# f28002x_wd_regs register map
Vendor: Texas Instruments
Peripheral module from a debugger description file (folder C2000).
Address unit: 16 bits
Registers are 16-bit, read-write, no defined reset value unless marked. A register's access mark holds for its fields unless they carry their own. Offsets are as the file gives them; lines under a group give offsets from that group; [hi:lo] are bit positions; {n}, {i} and the like mark numbered series; 'fields as' and 'values as' point back to an identical list; <NAME> marks a mode.

## WD_REGS — WD Registers
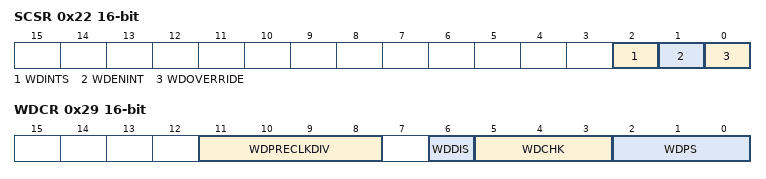
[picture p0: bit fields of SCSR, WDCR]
0x22 SCSR access per field — System Control and Status Register
  [2] WDINTS ro — WD Interrupt Status
  [1] WDENINT rw — WD Interrupt Enable
  [0] WDOVERRIDE rw — WD Override for WDDIS bit
0x23 WDCNTR ro — Watchdog Counter Register
  [7:0] WDCNTR — WD Counter
0x25 WDKEY — Watchdog Reset Key Register
  [7:0] WDKEY — Key to pet the watchdog timer.
0x29 WDCR — Watchdog Control Register
  [11:8] WDPRECLKDIV — WD Pre Clock Divider
  [6] WDDIS — WD Disable
  [5:3] WDCHK — WD Check Bits
  [2:0] WDPS — WD Clock Prescalar
0x2A WDWCR — Watchdog Windowed Control Register
  [7:0] MIN — WD Min Threshold setting for Windowed Watchdog functionality
